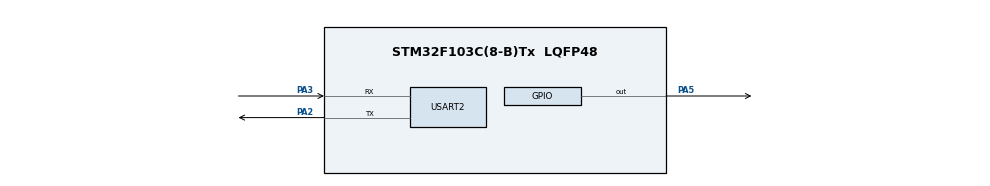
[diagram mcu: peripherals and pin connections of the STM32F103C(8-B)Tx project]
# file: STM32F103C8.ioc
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Mcu.Family=STM32F1
Mcu.Name=STM32F103C(8-B)Tx
Mcu.Package=LQFP48
NVIC.PriorityGroup=NVIC_PRIORITYGROUP_4
PA2.Mode=Asynchronous
PA2.Signal=USART2_TX
PA3.Mode=Asynchronous
PA3.Signal=USART2_RX
PA5.Signal=GPIO_Output
ProjectManager.HeapSize=0x200
ProjectManager.StackSize=0x400
ProjectManager.TargetToolchain=STM32CubeIDE
RCC.APB1Freq_Value=8000000
RCC.APB2Freq_Value=8000000
USART2.VirtualMode=VM_ASYNC
VP_SYS_VS_ND.Mode=No_Debug
board=custom

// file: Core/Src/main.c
/* USER CODE BEGIN Header */
/**
 ******************************************************************************
 * @file           : main.c
 * @brief          : Main program body
 ******************************************************************************
 * @attention
 *
 ******************************************************************************
 */
/* USER CODE END Header */
#include "main.h"

UART_HandleTypeDef huart2;

/* USER CODE BEGIN PV */
volatile uint8_t laser_state = 0;   // 0 - выключен, 1 - включен
uint8_t rx;
char buffer[10];
int idx = 0;
/* USER CODE END PV */

void SystemClock_Config(void);
static void MX_GPIO_Init(void);
static void MX_USART2_UART_Init(void);
/* USER CODE BEGIN PFP */
void process_cmd(char *cmd);
void uart_print(char *text);
/* USER CODE END PFP */

int main(void) {

	/* MCU Configuration--------------------------------------------------------*/

	/* Reset of all peripherals, Initializes the Flash interface and the Systick. */
	HAL_Init();

	/* Configure the system clock */
	SystemClock_Config();

	/* Initialize all configured peripherals */
	MX_GPIO_Init();
	MX_USART2_UART_Init();
	/* USER CODE BEGIN 2 */
	HAL_Delay(100);
	uart_print("STM32 READY\r\n");
	if (HAL_UART_Receive_IT(&huart2, &rx, 1) != HAL_OK) {
		Error_Handler();
	}
	/* USER CODE END 2 */

	/* Infinite loop */
	/* USER CODE BEGIN WHILE */
	while (1) {
		if (laser_state)
			HAL_GPIO_WritePin(GPIOA, GPIO_PIN_5, GPIO_PIN_SET);
		else
			HAL_GPIO_WritePin(GPIOA, GPIO_PIN_5, GPIO_PIN_RESET);

		HAL_Delay(1);
		/* USER CODE END WHILE */

	}
}

void SystemClock_Config(void) {
	RCC_OscInitTypeDef RCC_OscInitStruct = { 0 };
	RCC_ClkInitTypeDef RCC_ClkInitStruct = { 0 };

	/** Initializes the RCC Oscillators according to the specified parameters
	 * in the RCC_OscInitTypeDef structure.
	 */
	RCC_OscInitStruct.OscillatorType = RCC_OSCILLATORTYPE_HSI;
	RCC_OscInitStruct.HSIState = RCC_HSI_ON;
	RCC_OscInitStruct.HSICalibrationValue = RCC_HSICALIBRATION_DEFAULT;
	RCC_OscInitStruct.PLL.PLLState = RCC_PLL_NONE;
	if (HAL_RCC_OscConfig(&RCC_OscInitStruct) != HAL_OK) {
		Error_Handler();
	}

	/** Initializes the CPU, AHB and APB buses clocks
	 */
	RCC_ClkInitStruct.ClockType = RCC_CLOCKTYPE_HCLK | RCC_CLOCKTYPE_SYSCLK
			| RCC_CLOCKTYPE_PCLK1 | RCC_CLOCKTYPE_PCLK2;
	RCC_ClkInitStruct.SYSCLKSource = RCC_SYSCLKSOURCE_HSI;
	RCC_ClkInitStruct.AHBCLKDivider = RCC_SYSCLK_DIV1;
	RCC_ClkInitStruct.APB1CLKDivider = RCC_HCLK_DIV1;
	RCC_ClkInitStruct.APB2CLKDivider = RCC_HCLK_DIV1;

	if (HAL_RCC_ClockConfig(&RCC_ClkInitStruct, FLASH_LATENCY_0) != HAL_OK) {
		Error_Handler();
	}
}

static void MX_USART2_UART_Init(void) {

	HAL_NVIC_SetPriority(USART2_IRQn, 0, 0);
	HAL_NVIC_EnableIRQ(USART2_IRQn);
	huart2.Instance = USART2;
	huart2.Init.BaudRate = 115200;
	huart2.Init.WordLength = UART_WORDLENGTH_8B;
	huart2.Init.StopBits = UART_STOPBITS_1;
	huart2.Init.Parity = UART_PARITY_NONE;
	huart2.Init.Mode = UART_MODE_TX_RX;
	huart2.Init.HwFlowCtl = UART_HWCONTROL_NONE;
	huart2.Init.OverSampling = UART_OVERSAMPLING_16;
	if (HAL_UART_Init(&huart2) != HAL_OK) {
		Error_Handler();
	}

}

static void MX_GPIO_Init(void) {
	GPIO_InitTypeDef GPIO_InitStruct = { 0 };

	/* GPIO Ports Clock Enable */
	__HAL_RCC_GPIOA_CLK_ENABLE();

	/*Configure GPIO pin Output Level */
	HAL_GPIO_WritePin(GPIOA, GPIO_PIN_5, GPIO_PIN_RESET);

	/*Configure GPIO pin : PA5 */
	GPIO_InitStruct.Pin = GPIO_PIN_5;
	GPIO_InitStruct.Mode = GPIO_MODE_OUTPUT_PP;
	GPIO_InitStruct.Pull = GPIO_NOPULL;
	GPIO_InitStruct.Speed = GPIO_SPEED_FREQ_LOW;
	HAL_GPIO_Init(GPIOA, &GPIO_InitStruct);

}

/* USER CODE BEGIN 4 */
/* UART callback  */
void HAL_UART_RxCpltCallback(UART_HandleTypeDef *huart) {
	// Как только пришёл первый байт — выводим сообщение
	uart_print("1 byte received\r\n");

	if (huart != &huart2)
		return;

	if (rx == '\r' || rx == '\n') // Завершение команды
			{
		buffer[idx] = 0;      // Завершаем строку
		process_cmd(buffer);  // Обрабатываем команду
		idx = 0;              // Сбрасываем индекс
	} else if (rx == '\n') {
		// Игнорируем LF, если терминал шлёт \r\n
	} else {
		if (idx < sizeof(buffer) - 1)
			buffer[idx++] = rx; // Добавляем символ в буфер
	}

	// Перезапуск приёма
	HAL_UART_Receive_IT(&huart2, &rx, 1);
}

// Command processing
void process_cmd(char *cmd) {
	uart_print("RX=");
	uart_print(cmd);
	uart_print("\r\n");

	if (strcmp(cmd, "ON") == 0) {
		laser_state = 1;
		uart_print("LASER ON\r\n");
	} else if (strcmp(cmd, "OFF") == 0) {
		laser_state = 0;
		uart_print("LASER OFF\r\n");
	} else {
		uart_print("UNKNOWN CMD\r\n");
	}
}

// UART transmit helper
void uart_print(char *text) {
	HAL_UART_Transmit(&huart2, (uint8_t*) text, strlen(text), HAL_MAX_DELAY);
}

// Optional IRQ handler
void USART2_IRQHandler(void) {
	HAL_UART_IRQHandler(&huart2);
}
/* USER CODE END 4 */

void Error_Handler(void) {
	__disable_irq();
	while (1) {
	}
}
